# f2838x_nmi_intrupt_regs register map
Vendor: Texas Instruments
Peripheral module from a debugger description file (folder C2000).
Address unit: 16 bits
Registers are 16-bit, read-write, no defined reset value unless marked. A register's access mark holds for its fields unless they carry their own. Offsets are as the file gives them; lines under a group give offsets from that group; [hi:lo] are bit positions; {n}, {i} and the like mark numbered series; 'fields as' and 'values as' point back to an identical list; <NAME> marks a mode.

## NMI_INTRUPT_REGS — NMI INTRUPT Registers
0x00 NMICFG — NMI Configuration Register
  [0] NMIE — Global NMI Enable
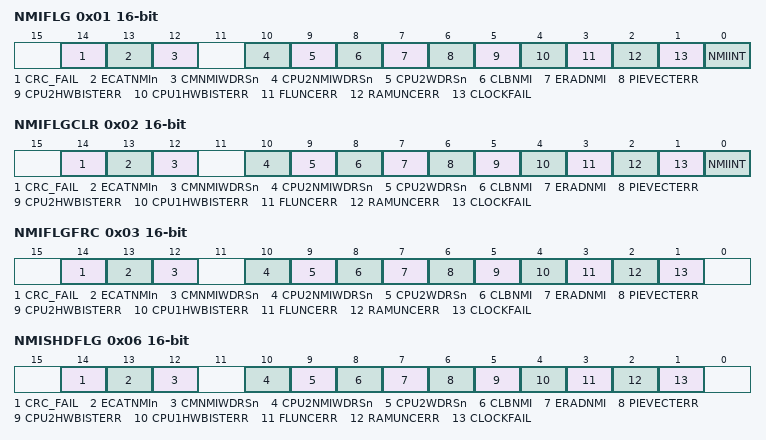
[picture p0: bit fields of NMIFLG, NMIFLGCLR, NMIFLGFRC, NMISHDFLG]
0x01 NMIFLG ro — NMI Flag Register (SYSRsn Clear)
  [14] CRC_FAIL — CRC calculation failed.
  [13] ECATNMIn — NMI from EtherCAT reset out
  [12] CMNMIWDRSn — CM NMI watch dog has timed out.
  [10] CPU2NMIWDRSn — CPU2 NMIWDRSn Reset Indication Flag
  [9] CPU2WDRSn — CPU2 WDRSn Reset Indication Flag
  [8] CLBNMI — Configurable Logic Block NMI Flag
  [7] ERADNMI — ERAD Module NMI Flag
  [6] PIEVECTERR — PIE Vector Fetch Error Flag
  [5] CPU2HWBISTERR — HW BIST Error NMI Flag
  [4] CPU1HWBISTERR — HW BIST Error NMI Flag
  [3] FLUNCERR — Flash Uncorrectable Error NMI Flag
  [2] RAMUNCERR — RAM Uncorrectable Error NMI Flag
  [1] CLOCKFAIL — Clock Fail Interrupt Flag
  [0] NMIINT — NMI Interrupt Flag
0x02 NMIFLGCLR — NMI Flag Clear Register
  [14] CRC_FAIL — CRC_FAIL flag clear
  [13] ECATNMIn — ECATNMIn flag clear
  [12] CMNMIWDRSn — DCDCOLF Flag Clear
  [10] CPU2NMIWDRSn — CPU2NMIWDRSn Flag Clear
  [9] CPU2WDRSn — CPU2WDRSn Flag Clear
  [8] CLBNMI — CLBNMI Flag Clear
  [7] ERADNMI — ERADNMI Flag Clear
  [6] PIEVECTERR — PIEVECTERR Flag Clear
  [5] CPU2HWBISTERR — CPU2HWBISTERR Flag Clear
  [4] CPU1HWBISTERR — CPU1HWBISTERR Flag Clear
  [3] FLUNCERR — FLUNCERR Flag Clear
  [2] RAMUNCERR — RAMUNCERR Flag Clear
  [1] CLOCKFAIL — CLOCKFAIL Flag Clear
  [0] NMIINT — NMIINT Flag Clear
0x03 NMIFLGFRC — NMI Flag Force Register
  [14] CRC_FAIL — CRC_FAIL flag force
  [13] ECATNMIn — ECATNMIn flag force
  [12] CMNMIWDRSn — DCDCOLF Flag Force
  [10] CPU2NMIWDRSn — CPU2NMIWDRSn Flag Force
  [9] CPU2WDRSn — CPU2WDRSn Flag Force
  [8] CLBNMI — CLBNMI Flag Force
  [7] ERADNMI — ERADNMI Flag Force
  [6] PIEVECTERR — PIEVECTERR Flag Force
  [5] CPU2HWBISTERR — CPU2HWBISTERR Flag Force
  [4] CPU1HWBISTERR — CPU1HWBISTERR Flag Force
  [3] FLUNCERR — FLUNCERR Flag Force
  [2] RAMUNCERR — RAMUNCERR Flag Force
  [1] CLOCKFAIL — CLOCKFAIL Flag Force
0x04 NMIWDCNT ro — NMI Watchdog Counter Register
  [15:0] NMIWDCNT — NMI Watchdog Counter
0x05 NMIWDPRD — NMI Watchdog Period Register
  [15:0] NMIWDPRD — NMI Watchdog Period
0x06 NMISHDFLG ro — NMI Shadow Flag Register
  [14] CRC_FAIL — CRC_FAIL flag
  [13] ECATNMIn — ECATNMIn flag
  [12] CMNMIWDRSn — Shadow DCDCOLF Flag
  [10] CPU2NMIWDRSn — Shadow CPU2NMIWDRSn Flag
  [9] CPU2WDRSn — Shadow CPU2WDRSn Flag
  [8] CLBNMI — Shadow CLBNMI Flag
  [7] ERADNMI — Shadow ERADNMI Flag
  [6] PIEVECTERR — Shadow PIEVECTERR Flag
  [5] CPU2HWBISTERR — Shadow CPU2HWBISTERR Flag
  [4] CPU1HWBISTERR — Shadow CPU1HWBISTERR Flag
  [3] FLUNCERR — Shadow FLUNCERR Flag
  [2] RAMUNCERR — Shadow RAMUNCERR Flag
  [1] CLOCKFAIL — Shadow CLOCKFAIL Flag
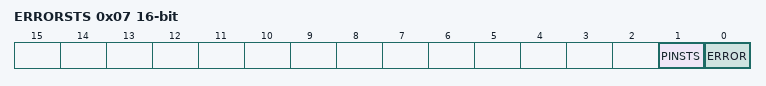
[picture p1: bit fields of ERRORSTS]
0x07 ERRORSTS ro — Error pin status
  [1] PINSTS — Error pin status.
  [0] ERROR — Error flag.
0x08 ERRORSTSCLR — ERRORSTS clear register
  [0] ERROR — ERRORFLG.ERROR clear bit
0x09 ERRORSTSFRC — ERRORSTS force register
  [0] ERROR — ERRORSTS.ERROR pin force.
0x0A ERRORCTL — Error pin control register
  [0] ERRORPOLSEL — ERROR pin polarity select
0x0B ERRORLOCK — Lock register to Error pin registers.
  [0] ERRORCTL — ERRORCTL Lock bit
